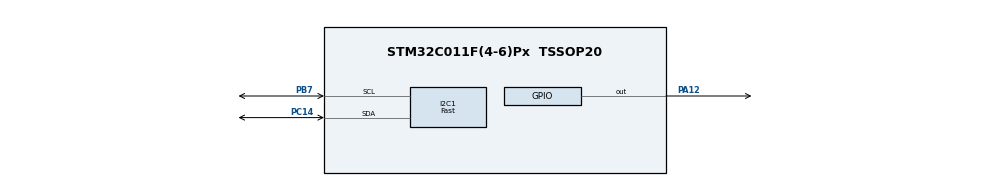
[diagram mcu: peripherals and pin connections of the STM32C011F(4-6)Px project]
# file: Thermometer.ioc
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I2C1.I2C_Speed_Mode=I2C_Fast
I2C1.Timing=0x00100205
IWDG.Prescaler=IWDG_PRESCALER_64
IWDG.Reload=2500
Mcu.Family=STM32C0
Mcu.Name=STM32C011F(4-6)Px
Mcu.Package=TSSOP20
PA12\ [PA10].Signal=GPIO_Output
PA13.Mode=Serial_Wire
PA13.Signal=DEBUG_SWDIO
PA14-BOOT0.Mode=Serial_Wire
PA14-BOOT0.Signal=DEBUG_SWCLK
PB7.Mode=I2C
PB7.Signal=I2C1_SCL
PC14-OSCX_IN\ (PC14).Mode=I2C
PC14-OSCX_IN\ (PC14).Signal=I2C1_SDA
ProjectManager.HeapSize=0x200
ProjectManager.StackSize=0x400
ProjectManager.TargetToolchain=STM32CubeIDE
RCC.ADCFreq_Value=6000000
RCC.AHBFreq_Value=6000000
RCC.CortexFreq_Value=6000000
RCC.EXTERNAL_CLOCK_VALUE=12288000
RCC.HCLKFreq_Value=6000000
RCC.HSE_VALUE=8000000
RCC.HSISYSCLKDivider=RCC_HSI_DIV8
RCC.HSI_VALUE=48000000
RCC.LSE_VALUE=32768
RCC.SYSCLKFreq_VALUE=6000000
VP_IWDG_VS_IWDG.Mode=IWDG_Activate
board=custom

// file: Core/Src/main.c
/* USER CODE BEGIN Header */
/**
  ******************************************************************************
  * @file           : main.c
  * @brief          : Main program body
  ******************************************************************************
  * @attention
  *
  * Copyright (c) 2025 STMicroelectronics.
  * All rights reserved.
  *
  * This software is licensed under terms that can be found in the LICENSE file
  * in the root directory of this software component.
  * If no LICENSE file comes with this software, it is provided AS-IS.
  *
  ******************************************************************************
  */
/* USER CODE END Header */
#include "main.h"

/* USER CODE BEGIN Includes */
#include <string.h>
#include <math.h>
#include <stdio.h>
#include "PCF85176.h"
#include "AT30TSE75.h"
/* USER CODE END Includes */

I2C_HandleTypeDef hi2c1;

IWDG_HandleTypeDef hiwdg;

void SystemClock_Config(void);
static void MX_GPIO_Init(void);
static void MX_I2C1_Init(void);
static void MX_IWDG_Init(void);

int main(void)
{

  /* MCU Configuration--------------------------------------------------------*/

  /* Reset of all peripherals, Initializes the Flash interface and the Systick. */
  HAL_Init();

  /* Configure the system clock */
  SystemClock_Config();

  /* Initialize all configured peripherals */
  MX_GPIO_Init();
  MX_I2C1_Init();
  MX_IWDG_Init();

  /* Infinite loop */
  /* USER CODE BEGIN WHILE */
  AT30TSE75 sensor;
  AT30TSE75_Initalise(&sensor, &hi2c1);
  HAL_Delay(1);
  PCF85176 display;
  PCF85176_Initalise(&display, &hi2c1);

  float temperature = AT30TSE75_ReadTemperature(&sensor);
  temperature = roundf(temperature * 10.0f) / 10.0f; // Round to 1 decimal point

  double intPart, fracPart;
  fracPart = modf(temperature, &intPart) * 10.0;

  // Count the digits in the int part to determine the decimal point position
  int digitCount = 0;
  int temp = (int)intPart;
  while (temp != 0) {
	  temp /= 10;
	  digitCount++;
  }

  char buf[4];
  sprintf(buf, "%d%d", (int)intPart, (int)fracPart);

  PCF85176_DisplayString(&display, buf, digitCount);

  // This enters standby mode which will cause the MCU to restart on wake up through the IWDG
   HAL_PWR_EnterSTANDBYMode();

    /* USER CODE END WHILE */

}

void SystemClock_Config(void)
{
  RCC_OscInitTypeDef RCC_OscInitStruct = {0};
  RCC_ClkInitTypeDef RCC_ClkInitStruct = {0};

  __HAL_FLASH_SET_LATENCY(FLASH_LATENCY_0);

  /** Initializes the RCC Oscillators according to the specified parameters
  * in the RCC_OscInitTypeDef structure.
  */
  RCC_OscInitStruct.OscillatorType = RCC_OSCILLATORTYPE_HSI|RCC_OSCILLATORTYPE_LSI;
  RCC_OscInitStruct.HSIState = RCC_HSI_ON;
  RCC_OscInitStruct.HSIDiv = RCC_HSI_DIV8;
  RCC_OscInitStruct.HSICalibrationValue = RCC_HSICALIBRATION_DEFAULT;
  RCC_OscInitStruct.LSIState = RCC_LSI_ON;
  if (HAL_RCC_OscConfig(&RCC_OscInitStruct) != HAL_OK)
  {
    Error_Handler();
  }

  /** Initializes the CPU, AHB and APB buses clocks
  */
  RCC_ClkInitStruct.ClockType = RCC_CLOCKTYPE_HCLK|RCC_CLOCKTYPE_SYSCLK
                              |RCC_CLOCKTYPE_PCLK1;
  RCC_ClkInitStruct.SYSCLKSource = RCC_SYSCLKSOURCE_HSI;
  RCC_ClkInitStruct.SYSCLKDivider = RCC_SYSCLK_DIV1;
  RCC_ClkInitStruct.AHBCLKDivider = RCC_HCLK_DIV1;
  RCC_ClkInitStruct.APB1CLKDivider = RCC_APB1_DIV1;

  if (HAL_RCC_ClockConfig(&RCC_ClkInitStruct, FLASH_LATENCY_0) != HAL_OK)
  {
    Error_Handler();
  }
}

static void MX_I2C1_Init(void)
{

  hi2c1.Instance = I2C1;
  hi2c1.Init.Timing = 0x00100205;
  hi2c1.Init.OwnAddress1 = 0;
  hi2c1.Init.AddressingMode = I2C_ADDRESSINGMODE_7BIT;
  hi2c1.Init.DualAddressMode = I2C_DUALADDRESS_DISABLE;
  hi2c1.Init.OwnAddress2 = 0;
  hi2c1.Init.OwnAddress2Masks = I2C_OA2_NOMASK;
  hi2c1.Init.GeneralCallMode = I2C_GENERALCALL_DISABLE;
  hi2c1.Init.NoStretchMode = I2C_NOSTRETCH_DISABLE;
  if (HAL_I2C_Init(&hi2c1) != HAL_OK)
  {
    Error_Handler();
  }

  /** Configure Analogue filter
  */
  if (HAL_I2CEx_ConfigAnalogFilter(&hi2c1, I2C_ANALOGFILTER_ENABLE) != HAL_OK)
  {
    Error_Handler();
  }

  /** Configure Digital filter
  */
  if (HAL_I2CEx_ConfigDigitalFilter(&hi2c1, 0) != HAL_OK)
  {
    Error_Handler();
  }

}

static void MX_IWDG_Init(void)
{

  hiwdg.Instance = IWDG;
  hiwdg.Init.Prescaler = IWDG_PRESCALER_64;
  hiwdg.Init.Window = 4095;
  hiwdg.Init.Reload = 2500;
  if (HAL_IWDG_Init(&hiwdg) != HAL_OK)
  {
    Error_Handler();
  }

}

static void MX_GPIO_Init(void)
{
  GPIO_InitTypeDef GPIO_InitStruct = {0};

  /* GPIO Ports Clock Enable */
  __HAL_RCC_GPIOB_CLK_ENABLE();
  __HAL_RCC_GPIOC_CLK_ENABLE();
  __HAL_RCC_GPIOA_CLK_ENABLE();

  /*Configure GPIO pin Output Level */
  HAL_GPIO_WritePin(GPIOA, GPIO_PIN_12, GPIO_PIN_RESET);

  /*Configure GPIO pin : PA12 */
  GPIO_InitStruct.Pin = GPIO_PIN_12;
  GPIO_InitStruct.Mode = GPIO_MODE_OUTPUT_PP;
  GPIO_InitStruct.Pull = GPIO_NOPULL;
  GPIO_InitStruct.Speed = GPIO_SPEED_FREQ_LOW;
  HAL_GPIO_Init(GPIOA, &GPIO_InitStruct);

}

void Error_Handler(void)
{
  __disable_irq();
  while (1)
  {
  }
}
